# LPC845 register map
Vendor: NXP Semiconductors; Series: LPC; File version: 1.6
CPU: CM0PLUS r0p0, little endian, no MPU, no FPU, VTOR, 2 interrupt priority bits
Registers are 32-bit, read-write, reset 0x0 unless marked. A register's access mark holds for its fields unless they carry their own. Offsets are from the block's base; [hi:lo] are bit positions; {n}, {i} and the like mark numbered series.

## MRT0 — LPC84x Multi-Rate Timer (MRT)
Base 0x40004000
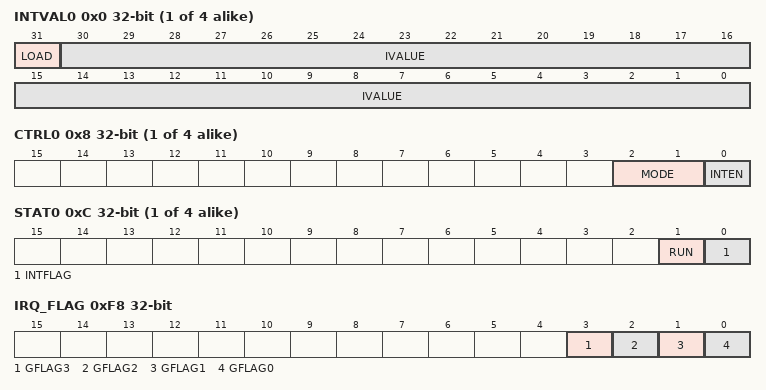
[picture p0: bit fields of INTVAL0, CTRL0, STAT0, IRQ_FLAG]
{0x0+0x10*i} INTVAL{i} (reset mask 0x80FFFFFF) (i=0..3) — MRT Time interval value register. This value is loaded into the TIMER register.
  [31] LOAD — Determines how the timer interval value IVALUE -1 is loaded into the TIMERn register. This bit is write-only. Reading this bit always returns 0.
    0=No force load. The load from the INTVALn register to the TIMERn register is processed at the end of the time interval if the repeat mode is selected.; 1=Force load. The INTVALn interval value IVALUE -1 is immediately loaded into the TIMERn register while TIMERn is running.
  [30:0] IVALUE — Time interval load value. This value is loaded into the TIMERn register and the MRT channel n starts counting down from IVALUE -1. If the timer is idle, writing a non-zero value to this bit field starts the timer immediately. If the timer is running, writing a zero to this bit field does the following: If LOAD = 1, the timer stops immediately. If LOAD = 0, the timer stops at the end of the time interval.
{0x4+0x10*i} TIMER{i} ro reset 0xFFFFFF (reset mask 0xFFFFFF) (i=0..3) — MRT Timer register. This register reads the value of the down-counter.
  [30:0] VALUE — Holds the current timer value of the down-counter. The initial value of the TIMERn register is loaded as IVALUE - 1 from the INTVALn register either at the end of the time interval or immediately in the following cases: INTVALn register is updated in the idle state. INTVALn register is updated with LOAD = 1. When the timer is in idle state, reading this bit fields returns -1 (0x00FF FFFF).
{0x8+0x10*i} CTRL{i} (i=0..3) — MRT Control register. This register controls the MRT modes.
  [2:1] MODE — Selects timer mode.
    0=Repeat interrupt mode; 1=One-shot interrupt mode; 2=One-shot stall mode
  [0] INTEN — Enable the TIMERn interrupt.
    0=Disabled. TIMERn interrupt is disabled.; 1=Enabled. TIMERn interrupt is enabled.
{0xC+0x10*i} STAT{i} (i=0..3) — MRT Status register.
  [1] RUN — Indicates the state of TIMERn. This bit is read-only.
    0=Idle state. TIMERn is stopped.; 1=Running. TIMERn is running.
  [0] INTFLAG — Monitors the interrupt flag.
    0=No pending interrupt. Writing a zero is equivalent to no operation.; 1=Pending interrupt. The interrupt is pending because TIMERn has reached the end of the time interval. If the INTEN bit in the CONTROLn is also set to 1, the interrupt for timer channel n and the global interrupt are raised. Writing a 1 to this bit clears the interrupt request.
0xF4 IDLE_CH ro — Idle channel register. This register returns the number of the first idle channel.
  [7:4] CHAN — Idle channel. Reading the CHAN bits, returns the lowest idle timer channel. The number is positioned such that it can be used as an offset from the MRT base address in order to access the registers for the allocated channel. If all timer channels are running, CHAN = 0xF. See text above for more details.
0xF8 IRQ_FLAG — Global interrupt flag register
  [3] GFLAG3 — Monitors the interrupt flag of TIMER3. See description of channel 0.
  [2] GFLAG2 — Monitors the interrupt flag of TIMER2. See description of channel 0.
  [1] GFLAG1 — Monitors the interrupt flag of TIMER1. See description of channel 0.
  [0] GFLAG0 — Monitors the interrupt flag of TIMER0.
    0=No pending interrupt. Writing a zero is equivalent to no operation.; 1=Pending interrupt. The interrupt is pending because TIMER0 has reached the end of the time interval. If the INTEN bit in the CONTROL0 register is also set to 1, the interrupt for timer channel 0 and the global interrupt are raised. Writing a 1 to this bit clears the interrupt request.

## Notices in the file
Copyright 2016-2019 NXP
All rights reserved.
SPDX-License-Identifier: BSD-3-Clause
